# SPC1169 register map
File version: 2022071043481212
CPU: cm4 r1p0, little endian, no MPU, FPU, 4 interrupt priority bits
Registers are 32-bit, read-write, reset 0x0 unless marked. A register's access mark holds for its fields unless they carry their own. Offsets are from the block's base; [hi:lo] are bit positions; {n}, {i} and the like mark numbered series.

## PINMUX
Base 0x40000300
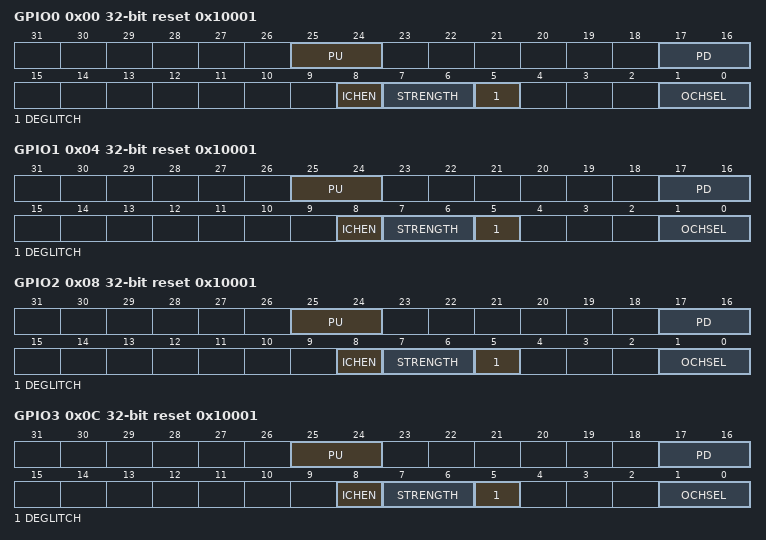
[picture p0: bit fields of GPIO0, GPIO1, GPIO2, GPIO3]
0x00 GPIO0 reset 0x10001 — GPIO0 Pin Control Register
  [25:24] PU — Pull up enable
  [17:16] PD — Pull down enable
  [8] ICHEN — Input channel enable
  [7:6] STRENGTH — Output driving strength
    0=5_MA; 1=10_MA; 2=15_MA; 3=20_MA
  [5] DEGLITCH — Input deglitch
    0=DISABLE; 1=ENABLE
  [1:0] OCHSEL — Output channel select
    0=GPIO0; 1=ANA_IN0; 2=PWM_SOCAO (PWM SOCA output for monitor); 3=PWM_SOCCO (PWM SOCC output for monitor)
0x04 GPIO1 reset 0x10001 — GPIO1 Pin Control Register
  [25:24] PU — Pull up enable
  [17:16] PD — Pull down enable
  [8] ICHEN — Input channel enable
  [7:6] STRENGTH — Output driving strength
    0=5_MA; 1=10_MA; 2=15_MA; 3=20_MA
  [5] DEGLITCH — Input deglitch
    0=DISABLE; 1=ENABLE
  [1:0] OCHSEL — Output channel select
    0=GPIO1; 1=ANA_IN1; 2=PWM_SOCBO (PWM SOCB output for monitor); 3=ECAP_APWMO (ECAP APWM mode output)
0x08 GPIO2 reset 0x10001 — GPIO2 Pin Control Register
  [25:24] PU — Pull up enable
  [17:16] PD — Pull down enable
  [8] ICHEN — Input channel enable
  [7:6] STRENGTH — Output driving strength
    0=5_MA; 1=10_MA; 2=15_MA; 3=20_MA
  [5] DEGLITCH — Input deglitch
    0=DISABLE; 1=ENABLE
  [1:0] OCHSEL — Output channel select
    0=GPIO2; 1=ANA_IN2; 2=CLK_DCLK; 3=EPWR_TZO (EPWR_TZ output for monitor. It can be seleced from EPWR_TZ0 or EPWR_TZ1)
0x0C GPIO3 reset 0x10001 — GPIO3 Pin Control Register
  [25:24] PU — Pull up enable
  [17:16] PD — Pull down enable
  [8] ICHEN — Input channel enable
  [7:6] STRENGTH — Output driving strength
    0=5_MA; 1=10_MA; 2=15_MA; 3=20_MA
  [5] DEGLITCH — Input deglitch
    0=DISABLE; 1=ENABLE
  [1:0] OCHSEL — Output channel select
    0=GPIO3; 1=ANA_IN3; 2=XIN; 3=COMP_MON0
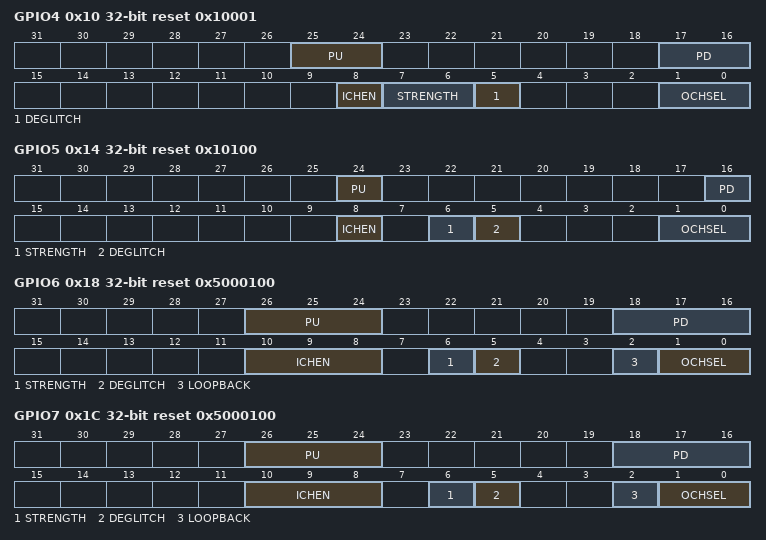
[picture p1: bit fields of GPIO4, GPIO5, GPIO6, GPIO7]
0x10 GPIO4 reset 0x10001 — GPIO4 Pin Control Register
  [25:24] PU — Pull up enable
  [17:16] PD — Pull down enable
  [8] ICHEN — Input channel enable
  [7:6] STRENGTH — Output driving strength
    0=5_MA; 1=10_MA; 2=15_MA; 3=20_MA
  [5] DEGLITCH — Input deglitch
    0=DISABLE; 1=ENABLE
  [1:0] OCHSEL — Output channel select
    0=GPIO4; 1=ANA_IN4; 2=XOUT; 3=COMP_MON1
0x14 GPIO5 reset 0x10100 — GPIO5 Pin Control Register
  [24] PU — Pull up enable
  [16] PD — Pull down enable
  [8] ICHEN — Input channel enable
  [6] STRENGTH — Output driving strength
    0=1_MA; 1=20_MA
  [5] DEGLITCH — Input deglitch
    0=DISABLE; 1=ENABLE
  [1:0] OCHSEL — Output channel select
    0=GPIO5; 1=EPWR_TZO (EPWR_TZ output for monitor. It can be seleced from EPWR_TZ0 or EPWR_TZ1); 2=PWM_SOCO (PWM SOC output for monitor. It is logic OR of PWM_SOCAO, PWM_SOCBO and PWM_SOCCO); 3=ECAP_APWMO (ECAP APWM mode output)
0x18 GPIO6 reset 0x5000100 — GPIO6 Pin Control Register
  [26:24] PU — Pull up enable
  [18:16] PD — Pull down enable
  [10:8] ICHEN — Input channel enable
  [6] STRENGTH — Output driving strength
    0=1_MA; 1=20_MA
  [5] DEGLITCH — Input deglitch
    0=DISABLE; 1=ENABLE
  [2] LOOPBACK — Data loopback for UART1
    0=DISABLE; 1=ENABLE
  [1:0] OCHSEL — Channel select
    0=GPIO6; 1=SPI0_SCLK; 2=UART1_TXD; 3=COMP_MON2
0x1C GPIO7 reset 0x5000100 — GPIO7 Pin Control Register
  [26:24] PU — Pull up enable
  [18:16] PD — Pull down enable
  [10:8] ICHEN — Input channel enable
  [6] STRENGTH — Output driving strength
    0=1_MA; 1=20_MA
  [5] DEGLITCH — Input deglitch
    0=DISABLE; 1=ENABLE
  [2] LOOPBACK — Data loopback for UART1
    0=DISABLE; 1=ENABLE
  [1:0] OCHSEL — Output channel select
    0=GPIO7; 1=SPI0_SFRM; 2=UART1_RXD; 3=COMP_MON2 (COMP_MON3)
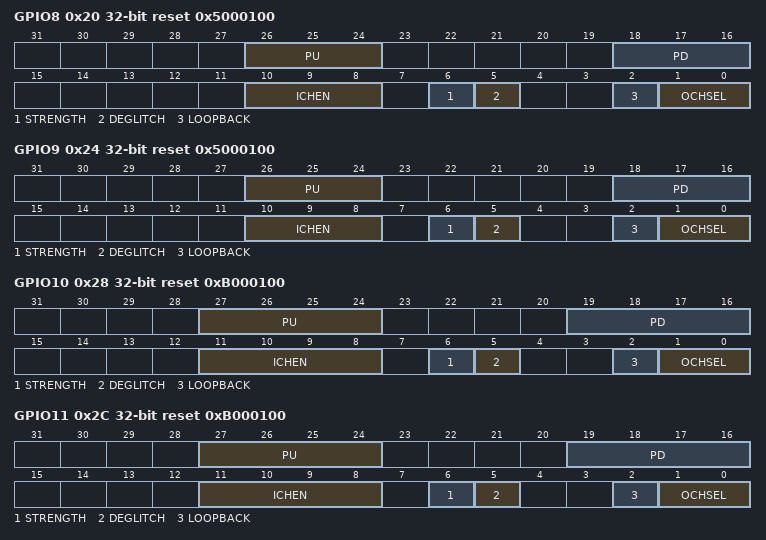
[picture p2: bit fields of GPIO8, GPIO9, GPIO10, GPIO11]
0x20 GPIO8 reset 0x5000100 — GPIO8 Pin Control Register
  [26:24] PU — Pull up enable
  [18:16] PD — Pull down enable
  [10:8] ICHEN — Input channel enable
  [6] STRENGTH — Output driving strength
    0=1_MA; 1=20_MA
  [5] DEGLITCH — Input deglitch
    0=DISABLE; 1=ENABLE
  [2] LOOPBACK — Data loopback for SPI0 and CAN
    0=DISABLE; 1=ENABLE
  [1:0] OCHSEL — Output channel select
    0=GPIO8; 1=SPI0_MOSI; 2=CAN_TXD; 3=COMP_MON4
0x24 GPIO9 reset 0x5000100 — GPIO9 Pin Control Register
  [26:24] PU — Pull up enable
  [18:16] PD — Pull down enable
  [10:8] ICHEN — Input channel enable
  [6] STRENGTH — Output driving strength
    0=1_MA; 1=20_MA
  [5] DEGLITCH — Input deglitch
    0=DISABLE; 1=ENABLE
  [2] LOOPBACK — Data loopback for SPI0 and CAN
    0=DISABLE; 1=ENABLE
  [1:0] OCHSEL — Output channel select
    0=GPIO9; 1=SPI0_MISO; 2=CAN_RXD; 3=COMP_MON5
0x28 GPIO10 reset 0xB000100 — GPIO10 Pin Control Register
  [27:24] PU — Pull up enable
  [19:16] PD — Pull down enable
  [11:8] ICHEN — Input channel enable
  [6] STRENGTH — Output driving strength
    0=1_MA; 1=20_MA
  [5] DEGLITCH — Input deglitch
    0=DISABLE; 1=ENABLE
  [2] LOOPBACK — Data loopback for UART0
    0=DISABLE; 1=ENABLE
  [1:0] OCHSEL — Output channel select
    0=GPIO10; 1=UART0_TXD; 2=PWM0A; 3=I2C_SCL
0x2C GPIO11 reset 0xB000100 — GPIO11 Pin Control Register
  [27:24] PU — Pull up enable
  [19:16] PD — Pull down enable
  [11:8] ICHEN — Input channel enable
  [6] STRENGTH — Output driving strength
    0=1_MA; 1=20_MA
  [5] DEGLITCH — Input deglitch
    0=DISABLE; 1=ENABLE
  [2] LOOPBACK — Data loopback for UART0
    0=DISABLE; 1=ENABLE
  [1:0] OCHSEL — Output channel select
    0=GPIO11; 1=UART0_RXD; 2=PWM0B; 3=I2C_SDA
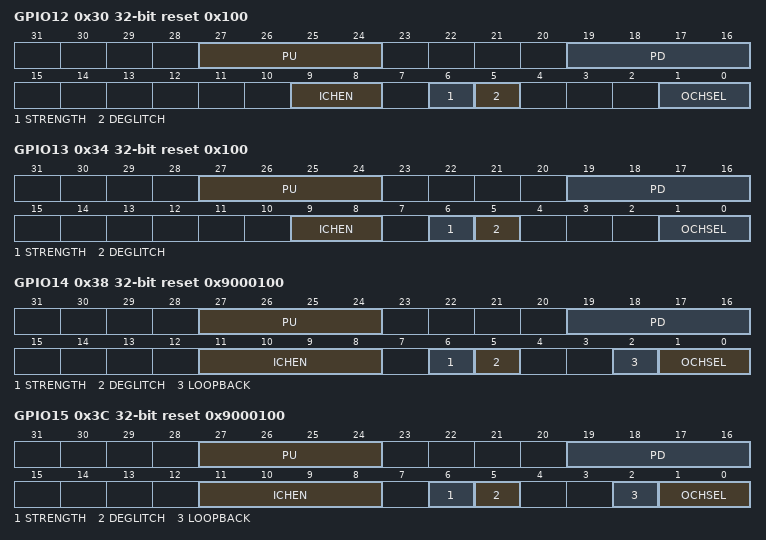
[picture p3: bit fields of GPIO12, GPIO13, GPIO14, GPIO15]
0x30 GPIO12 reset 0x100 — GPIO12 Pin Control Register
  [27:24] PU — Pull up enable
  [19:16] PD — Pull down enable
  [9:8] ICHEN — Input channel enable
  [6] STRENGTH — Output driving strength
    0=1_MA; 1=20_MA
  [5] DEGLITCH — Input deglitch
    0=DISABLE; 1=ENABLE
  [1:0] OCHSEL — Output channel select
    0=GPIO12; 1=SPI1_SCLK; 2=PWM1A; 3=PWM3A
0x34 GPIO13 reset 0x100 — GPIO13 Pin Control Register
  [27:24] PU — Pull up enable
  [19:16] PD — Pull down enable
  [9:8] ICHEN — Input channel enable
  [6] STRENGTH — Output driving strength
    0=1_MA; 1=20_MA
  [5] DEGLITCH — Input deglitch
    0=DISABLE; 1=ENABLE
  [1:0] OCHSEL — Output channel select
    0=GPIO13; 1=SPI1_SFRM; 2=PWM1B; 3=PWM3B
0x38 GPIO14 reset 0x9000100 — GPIO14 Pin Control Register
  [27:24] PU — Pull up enable
  [19:16] PD — Pull down enable
  [11:8] ICHEN — Input channel enable
  [6] STRENGTH — Output driving strength
    0=1_MA; 1=20_MA
  [5] DEGLITCH — Input deglitch
    0=DISABLE; 1=ENABLE
  [2] LOOPBACK — Data loopback for SPI1
    0=DISABLE; 1=ENABLE
  [1:0] OCHSEL — Output channel select
    0=GPIO14; 1=SPI1_MOSI; 2=PWM2A; 3=I2C_SCL
0x3C GPIO15 reset 0x9000100 — GPIO15 Pin Control Register
  [27:24] PU — Pull up enable
  [19:16] PD — Pull down enable
  [11:8] ICHEN — Input channel enable
  [6] STRENGTH — Output driving strength
    0=1_MA; 1=20_MA
  [5] DEGLITCH — Input deglitch
    0=DISABLE; 1=ENABLE
  [2] LOOPBACK — Data loopback for SPI1
    0=DISABLE; 1=ENABLE
  [1:0] OCHSEL — Output channel select
    0=GPIO15; 1=SPI1_MISO; 2=PWM2B; 3=I2C_SDA
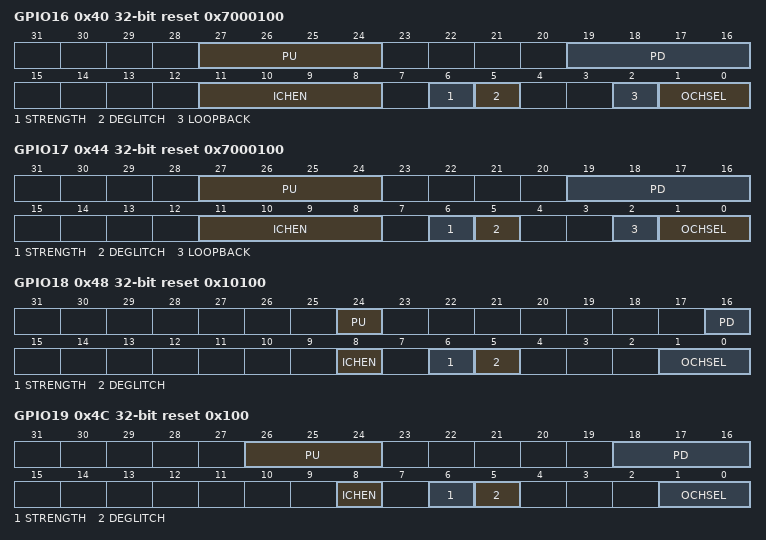
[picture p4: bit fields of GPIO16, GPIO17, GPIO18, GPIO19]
0x40 GPIO16 reset 0x7000100 — GPIO16 Pin Control Register
  [27:24] PU — Pull up enable
  [19:16] PD — Pull down enable
  [11:8] ICHEN — Input channel enable
  [6] STRENGTH — Output driving strength
    0=1_MA; 1=20_MA
  [5] DEGLITCH — Input deglitch
    0=DISABLE; 1=ENABLE
  [2] LOOPBACK — Data loopback for UART1 and CAN
    0=DISABLE; 1=ENABLE
  [1:0] OCHSEL — Output channel select
    0=GPIO16; 1=UART1_TXD; 2=CAN_TXD; 3=SPI1_SFRM
0x44 GPIO17 reset 0x7000100 — GPIO17 Pin Control Register
  [27:24] PU — Pull up enable
  [19:16] PD — Pull down enable
  [11:8] ICHEN — Input channel enable
  [6] STRENGTH — Output driving strength
    0=1_MA; 1=20_MA
  [5] DEGLITCH — Input deglitch
    0=DISABLE; 1=ENABLE
  [2] LOOPBACK — Data loopback for UART1 and CAN
    0=DISABLE; 1=ENABLE
  [1:0] OCHSEL — Output channel select
    0=GPIO17; 1=UART1_RXD; 2=CAN_RXD; 3=SPI1_SCLK
0x48 GPIO18 reset 0x10100 — GPIO18 Pin Control Register
  [24] PU — Pull up enable
  [16] PD — Pull down enable
  [8] ICHEN — Input channel enable
  [6] STRENGTH — Output driving strength
    0=1_MA; 1=20_MA
  [5] DEGLITCH — Input deglitch
    0=DISABLE; 1=ENABLE
  [1:0] OCHSEL — Output channel select
    0=GPIO18; 1=PWM_SOCO (PWM_SOC output for monitor. It is logic OR of PWM_SOCAO, PWM_SOCBO and PWM_SOCCO); 2=PWM_SYNCO (PWM_SYNC output for monitor); 3=ECAP_APWMO (ECAP APWM mode output)
0x4C GPIO19 reset 0x100 — GPIO19 Pin Control Register
  [26:24] PU — Pull up enable
  [18:16] PD — Pull down enable
  [8] ICHEN — Input channel enable
  [6] STRENGTH — Output driving strength
    0=1_MA; 1=20_MA
  [5] DEGLITCH — Input deglitch
    0=DISABLE; 1=ENABLE
  [1:0] OCHSEL — Output channel select
    0=GPIO19; 1=PWM2B; 2=PWM0A; 3=ECAP_APWMO (ECAP APWM mode output)
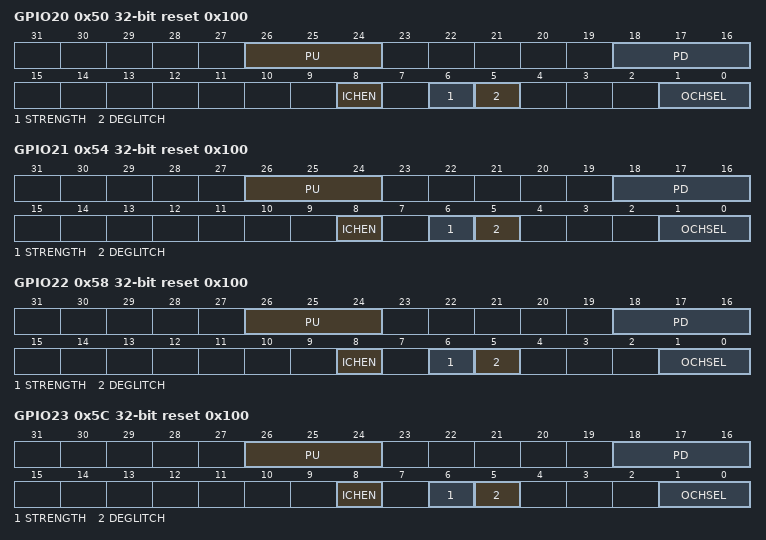
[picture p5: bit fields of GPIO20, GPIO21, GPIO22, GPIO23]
0x50 GPIO20 reset 0x100 — GPIO20 Pin Control Register
  [26:24] PU — Pull up enable
  [18:16] PD — Pull down enable
  [8] ICHEN — Input channel enable
  [6] STRENGTH — Output driving strength
    0=1_MA; 1=20_MA
  [5] DEGLITCH — Input deglitch
    0=DISABLE; 1=ENABLE
  [1:0] OCHSEL — Output channel select
    0=GPIO20; 1=PWM2A; 2=PWM1A; 3=ECAP_APWMO (ECAP APWM mode output)
0x54 GPIO21 reset 0x100 — GPIO21 Pin Control Register
  [26:24] PU — Pull up enable
  [18:16] PD — Pull down enable
  [8] ICHEN — Input channel enable
  [6] STRENGTH — Output driving strength
    0=1_MA; 1=20_MA
  [5] DEGLITCH — Input deglitch
    0=DISABLE; 1=ENABLE
  [1:0] OCHSEL — Output channel select
    0=GPIO21; 1=PWM1B; 2=PWM2A; 3=ECAP_APWMO (ECAP APWM mode output)
0x58 GPIO22 reset 0x100 — GPIO22 Pin Control Register
  [26:24] PU — Pull up enable
  [18:16] PD — Pull down enable
  [8] ICHEN — Input channel enable
  [6] STRENGTH — Output driving strength
    0=1_MA; 1=20_MA
  [5] DEGLITCH — Input deglitch
    0=DISABLE; 1=ENABLE
  [1:0] OCHSEL — Output channel select
    0=GPIO22; 1=PWM1A; 2=PWM0B; 3=ECAP_APWMO (ECAP APWM mode output)
0x5C GPIO23 reset 0x100 — GPIO23 Pin Control Register
  [26:24] PU — Pull up enable
  [18:16] PD — Pull down enable
  [8] ICHEN — Input channel enable
  [6] STRENGTH — Output driving strength
    0=1_MA; 1=20_MA
  [5] DEGLITCH — Input deglitch
    0=DISABLE; 1=ENABLE
  [1:0] OCHSEL — Output channel select
    0=GPIO23; 1=PWM0B; 2=PWM1B; 3=ECAP_APWMO (ECAP APWM mode output)
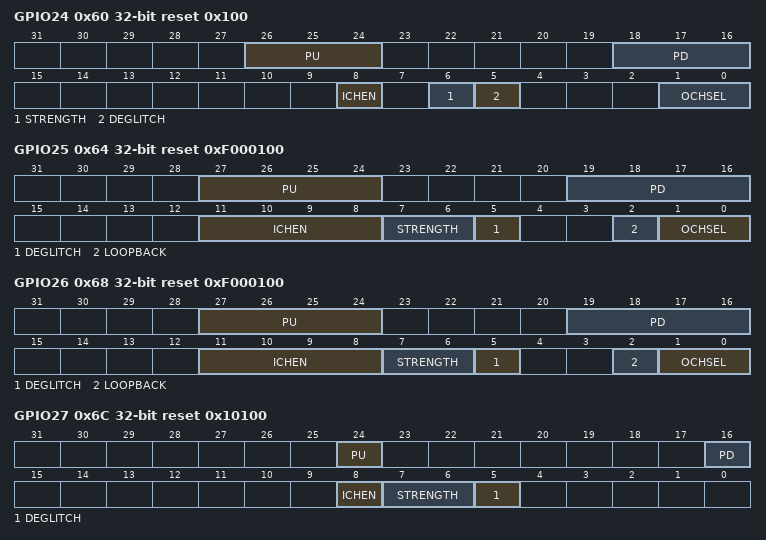
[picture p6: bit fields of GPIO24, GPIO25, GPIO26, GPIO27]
0x60 GPIO24 reset 0x100 — GPIO24 Pin Control Register
  [26:24] PU — Pull up enable
  [18:16] PD — Pull down enable
  [8] ICHEN — Input channel enable
  [6] STRENGTH — Output driving strength
    0=1_MA; 1=20_MA
  [5] DEGLITCH — Input deglitch
    0=DISABLE; 1=ENABLE
  [1:0] OCHSEL — Output channel select
    0=GPIO24; 1=PWM0A; 2=PWM2B; 3=ECAP_APWMO (ECAP APWM mode output)
0x64 GPIO25 reset 0xF000100 — GPIO25 Pin Control Register
  [27:24] PU — Pull up enable
  [19:16] PD — Pull down enable
  [11:8] ICHEN — Input channel enable
  [7:6] STRENGTH — Output driving strength
    0=5_MA; 1=10_MA; 2=15_MA; 3=20_MA
  [5] DEGLITCH — Input deglitch
    0=DISABLE; 1=ENABLE
  [2] LOOPBACK — Data loopback for UART1 and CAN
    0=DISABLE; 1=ENABLE
  [1:0] OCHSEL — Output channel select
    0=GPIO25; 1=UART1_TXD; 2=CAN_TXD; 3=I2C_SCL
0x68 GPIO26 reset 0xF000100 — GPIO26 Pin Control Register
  [27:24] PU — Pull up enable
  [19:16] PD — Pull down enable
  [11:8] ICHEN — Input channel enable
  [7:6] STRENGTH — Output driving strength
    0=5_MA; 1=10_MA; 2=15_MA; 3=20_MA
  [5] DEGLITCH — Input deglitch
    0=DISABLE; 1=ENABLE
  [2] LOOPBACK — Data loopback for UART1 and CAN
    0=DISABLE; 1=ENABLE
  [1:0] OCHSEL — Output channel select
    0=GPIO26; 1=UART1_RXD; 2=CAN_RXD; 3=I2C_SDA
0x6C GPIO27 reset 0x10100 — GPIO27 Pin Control Register
  [24] PU — Pull up enable
  [16] PD — Pull down enable
  [8] ICHEN — Input channel enable
  [7:6] STRENGTH — Output driving strength
    0=5_MA; 1=10_MA; 2=15_MA; 3=20_MA
  [5] DEGLITCH — Input deglitch
    0=DISABLE; 1=ENABLE
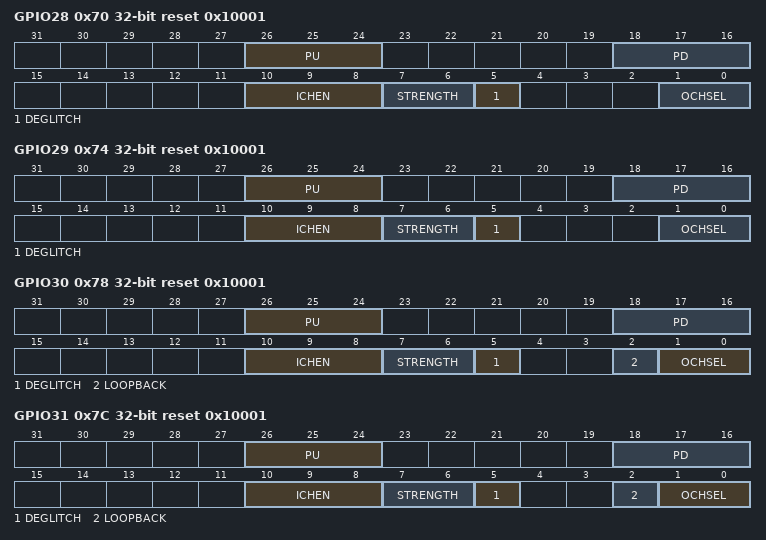
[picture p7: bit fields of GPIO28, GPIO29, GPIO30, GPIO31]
0x70 GPIO28 reset 0x10001 — GPIO28 Pin Control Register
  [26:24] PU — Pull up enable
  [18:16] PD — Pull down enable
  [10:8] ICHEN — Input channel enable
  [7:6] STRENGTH — Output driving strength
    0=5_MA; 1=10_MA; 2=15_MA; 3=20_MA
  [5] DEGLITCH — Input deglitch
    0=DISABLE; 1=ENABLE
  [1:0] OCHSEL — Output channel select
    0=GPIO28; 1=ANA_IN5; 2=SPI1_SCLK; 3=PWM_SOCAO (PWM SOCA output for monitor)
0x74 GPIO29 reset 0x10001 — GPIO29 Pin Control Register
  [26:24] PU — Pull up enable
  [18:16] PD — Pull down enable
  [10:8] ICHEN — Input channel enable
  [7:6] STRENGTH — Output driving strength
    0=5_MA; 1=10_MA; 2=15_MA; 3=20_MA
  [5] DEGLITCH — Input deglitch
    0=DISABLE; 1=ENABLE
  [1:0] OCHSEL — Output channel select
    0=GPIO29; 1=ANA_IN6; 2=SPI1_SFRM; 3=PWM_SOCBO (PWM SOCB output for monitor)
0x78 GPIO30 reset 0x10001 — GPIO30 Pin Control Register
  [26:24] PU — Pull up enable
  [18:16] PD — Pull down enable
  [10:8] ICHEN — Input channel enable
  [7:6] STRENGTH — Output driving strength
    0=5_MA; 1=10_MA; 2=15_MA; 3=20_MA
  [5] DEGLITCH — Input deglitch
    0=DISABLE; 1=ENABLE
  [2] LOOPBACK — Data loopback for SPI1
    0=DISABLE; 1=ENABLE
  [1:0] OCHSEL — Output channel select
    0=GPIO30; 1=ANA_IN7; 2=SPI1_MOSI; 3=PWM_SOCCO (PWM SOCC output for monitor)
0x7C GPIO31 reset 0x10001 — GPIO31 Pin Control Register
  [26:24] PU — Pull up enable
  [18:16] PD — Pull down enable
  [10:8] ICHEN — Input channel enable
  [7:6] STRENGTH — Output driving strength
    0=5_MA; 1=10_MA; 2=15_MA; 3=20_MA
  [5] DEGLITCH — Input deglitch
    0=DISABLE; 1=ENABLE
  [2] LOOPBACK — Data loopback for SPI1
    0=DISABLE; 1=ENABLE
  [1:0] OCHSEL — Output channel select
    0=GPIO31; 1=ANA_IN8; 2=SPI1_MISO; 3=PWM_SYNCO (PWM_SYNC output for monitor)
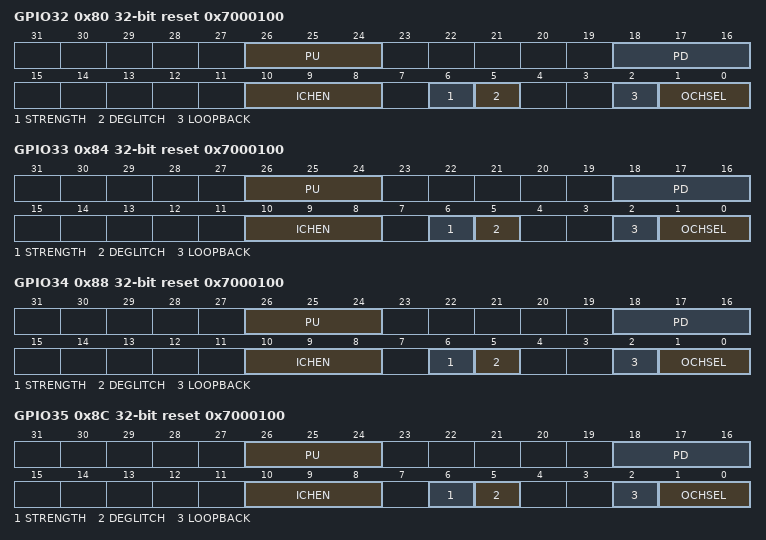
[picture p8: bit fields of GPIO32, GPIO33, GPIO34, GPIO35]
0x80 GPIO32 reset 0x7000100 — GPIO32 Pin Control Register
  [26:24] PU — Pull up enable
  [18:16] PD — Pull down enable
  [10:8] ICHEN — Input channel enable
  [6] STRENGTH — Output driving strength
    0=1_MA; 1=20_MA
  [5] DEGLITCH — Input deglitch
    0=DISABLE; 1=ENABLE
  [2] LOOPBACK — Data loopback for UART1
    0=DISABLE; 1=ENABLE
  [1:0] OCHSEL — Output channel select
    0=GPIO32; 1=UART1_TXD; 2=I2C_SCL; 3=COMP_MON6
0x84 GPIO33 reset 0x7000100 — GPIO33 Pin Control Register
  [26:24] PU — Pull up enable
  [18:16] PD — Pull down enable
  [10:8] ICHEN — Input channel enable
  [6] STRENGTH — Output driving strength
    0=1_MA; 1=20_MA
  [5] DEGLITCH — Input deglitch
    0=DISABLE; 1=ENABLE
  [2] LOOPBACK — Data loopback for UART1
    0=DISABLE; 1=ENABLE
  [1:0] OCHSEL — Output channel select
    0=GPIO33; 1=UART1_RXD; 2=I2C_SDA; 3=COMP_MON7
0x88 GPIO34 reset 0x7000100 — GPIO34 Pin Control Register
  [26:24] PU — Pull up enable
  [18:16] PD — Pull down enable
  [10:8] ICHEN — Input channel enable
  [6] STRENGTH — Output driving strength
    0=1_MA; 1=20_MA
  [5] DEGLITCH — Input deglitch
    0=DISABLE; 1=ENABLE
  [2] LOOPBACK — Data loopback for CAN
    0=DISABLE; 1=ENABLE
  [1:0] OCHSEL — Output channel select
    0=GPIO34; 1=CAN_TXD; 2=I2C_SCL; 3=EPWR_TZ0O (EPWR_TZ0 output for monitor)
0x8C GPIO35 reset 0x7000100 — GPIO35 Pin Control Register
  [26:24] PU — Pull up enable
  [18:16] PD — Pull down enable
  [10:8] ICHEN — Input channel enable
  [6] STRENGTH — Output driving strength
    0=1_MA; 1=20_MA
  [5] DEGLITCH — Input deglitch
    0=DISABLE; 1=ENABLE
  [2] LOOPBACK — Data loopback for CAN
    0=DISABLE; 1=ENABLE
  [1:0] OCHSEL — Output channel select
    0=GPIO35; 1=CAN_RXD; 2=I2C_SDA; 3=EPWR_TZ1O (EPWR_TZ1 output for monitor)
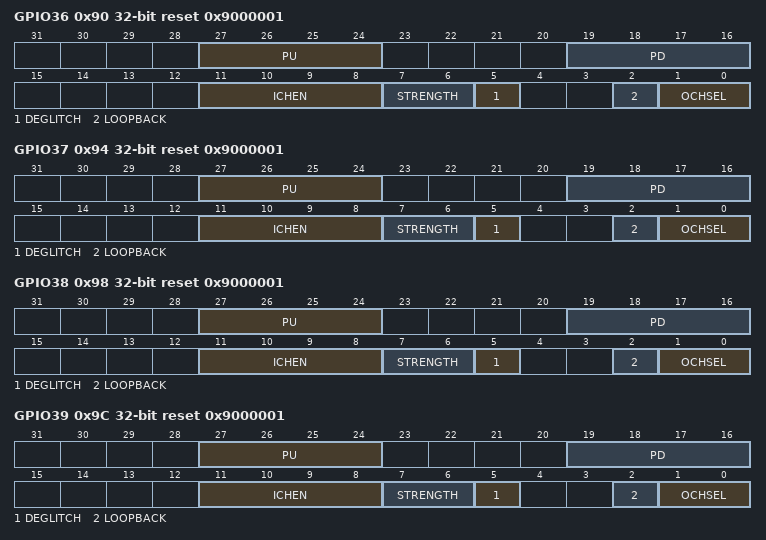
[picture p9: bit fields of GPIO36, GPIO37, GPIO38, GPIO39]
0x90 GPIO36 reset 0x9000001 — GPIO36 Pin Control Register
  [27:24] PU — Pull up enable
  [19:16] PD — Pull down enable
  [11:8] ICHEN — Input channel enable
  [7:6] STRENGTH — Output driving strength
    0=5_MA; 1=10_MA; 2=15_MA; 3=20_MA
  [5] DEGLITCH — Input deglitch
    0=DISABLE; 1=ENABLE
  [2] LOOPBACK — Data loopback for UART1
    0=DISABLE; 1=ENABLE
  [1:0] OCHSEL — Output channel select
    0=GPIO36; 1=ANA_PHU; 2=SPI1_SCLK; 3=UART1_TXD
0x94 GPIO37 reset 0x9000001 — GPIO37 Pin Control Register
  [27:24] PU — Pull up enable
  [19:16] PD — Pull down enable
  [11:8] ICHEN — Input channel enable
  [7:6] STRENGTH — Output driving strength
    0=5_MA; 1=10_MA; 2=15_MA; 3=20_MA
  [5] DEGLITCH — Input deglitch
    0=DISABLE; 1=ENABLE
  [2] LOOPBACK — Data loopback for UART1
    0=DISABLE; 1=ENABLE
  [1:0] OCHSEL — Output channel select
    0=GPIO37; 1=ANA_PHV; 2=SPI1_SFRM; 3=UART1_RXD
0x98 GPIO38 reset 0x9000001 — GPIO38 Pin Control Register
  [27:24] PU — Pull up enable
  [19:16] PD — Pull down enable
  [11:8] ICHEN — Input channel enable
  [7:6] STRENGTH — Output driving strength
    0=5_MA; 1=10_MA; 2=15_MA; 3=20_MA
  [5] DEGLITCH — Input deglitch
    0=DISABLE; 1=ENABLE
  [2] LOOPBACK — Data loopback for SPI1 and CAN
    0=DISABLE; 1=ENABLE
  [1:0] OCHSEL — Output channel select
    0=GPIO38; 1=ANA_PHW; 2=SPI1_MOSI; 3=CAN_TXD
0x9C GPIO39 reset 0x9000001 — GPIO39 Pin Control Register
  [27:24] PU — Pull up enable
  [19:16] PD — Pull down enable
  [11:8] ICHEN — Input channel enable
  [7:6] STRENGTH — Output driving strength
    0=5_MA; 1=10_MA; 2=15_MA; 3=20_MA
  [5] DEGLITCH — Input deglitch
    0=DISABLE; 1=ENABLE
  [2] LOOPBACK — Data loopback for SPI1 and CAN
    0=DISABLE; 1=ENABLE
  [1:0] OCHSEL — Output channel select
    0=GPIO39; 1=ANA_PHC; 2=SPI1_MISO; 3=CAN_RXD
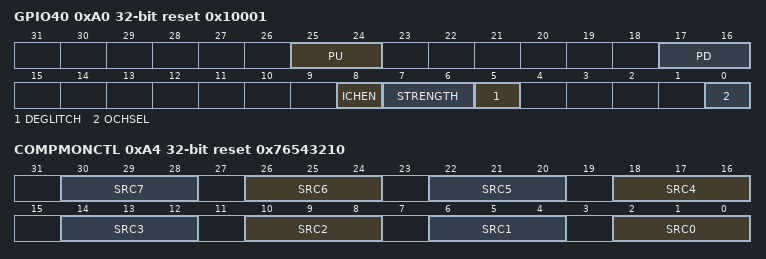
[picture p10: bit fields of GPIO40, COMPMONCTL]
0xA0 GPIO40 reset 0x10001 — GPIO40 Pin Control Register
  [25:24] PU — Pull up enable
  [17:16] PD — Pull down enable
  [8] ICHEN — Input channel enable
  [7:6] STRENGTH — Output driving strength
    0=5_MA; 1=10_MA; 2=15_MA; 3=20_MA
  [5] DEGLITCH — Input deglitch
    0=DISABLE; 1=ENABLE
  [0] OCHSEL — Output channel select
    0=GPIO40; 1=ANA_IN9
0xA4 COMPMONCTL reset 0x76543210 — Comparator Output Monitor Control Register
  [all] fields
    0=COMP0L (COMP0L output); 1=COMP0H (COMP0H output); 2=PHCOMPU (PHCOMPU original output); 3=PHCOMPV (PHCOMPV original output); 4=PHCOMPW (PHCOMPW original output); 5=PHCOMPUFLT (PHCOMPU filtered output); 6=PHCOMPVFLT (PHCOMPV filtered output); 7=PHCOMPWFLT (PHCOMPW filtered output)
  [4n+2:4n] SRC{n} (n=0..7) — COMP output monitor {n} source select
0xA8 PINMUXREGKEY reset 0x1ACCE551 — PINMUX Register Write-Allow Key Register
  [31:0] KEY — Write 0x1ACCE551 to unlock protected pinmux registers
